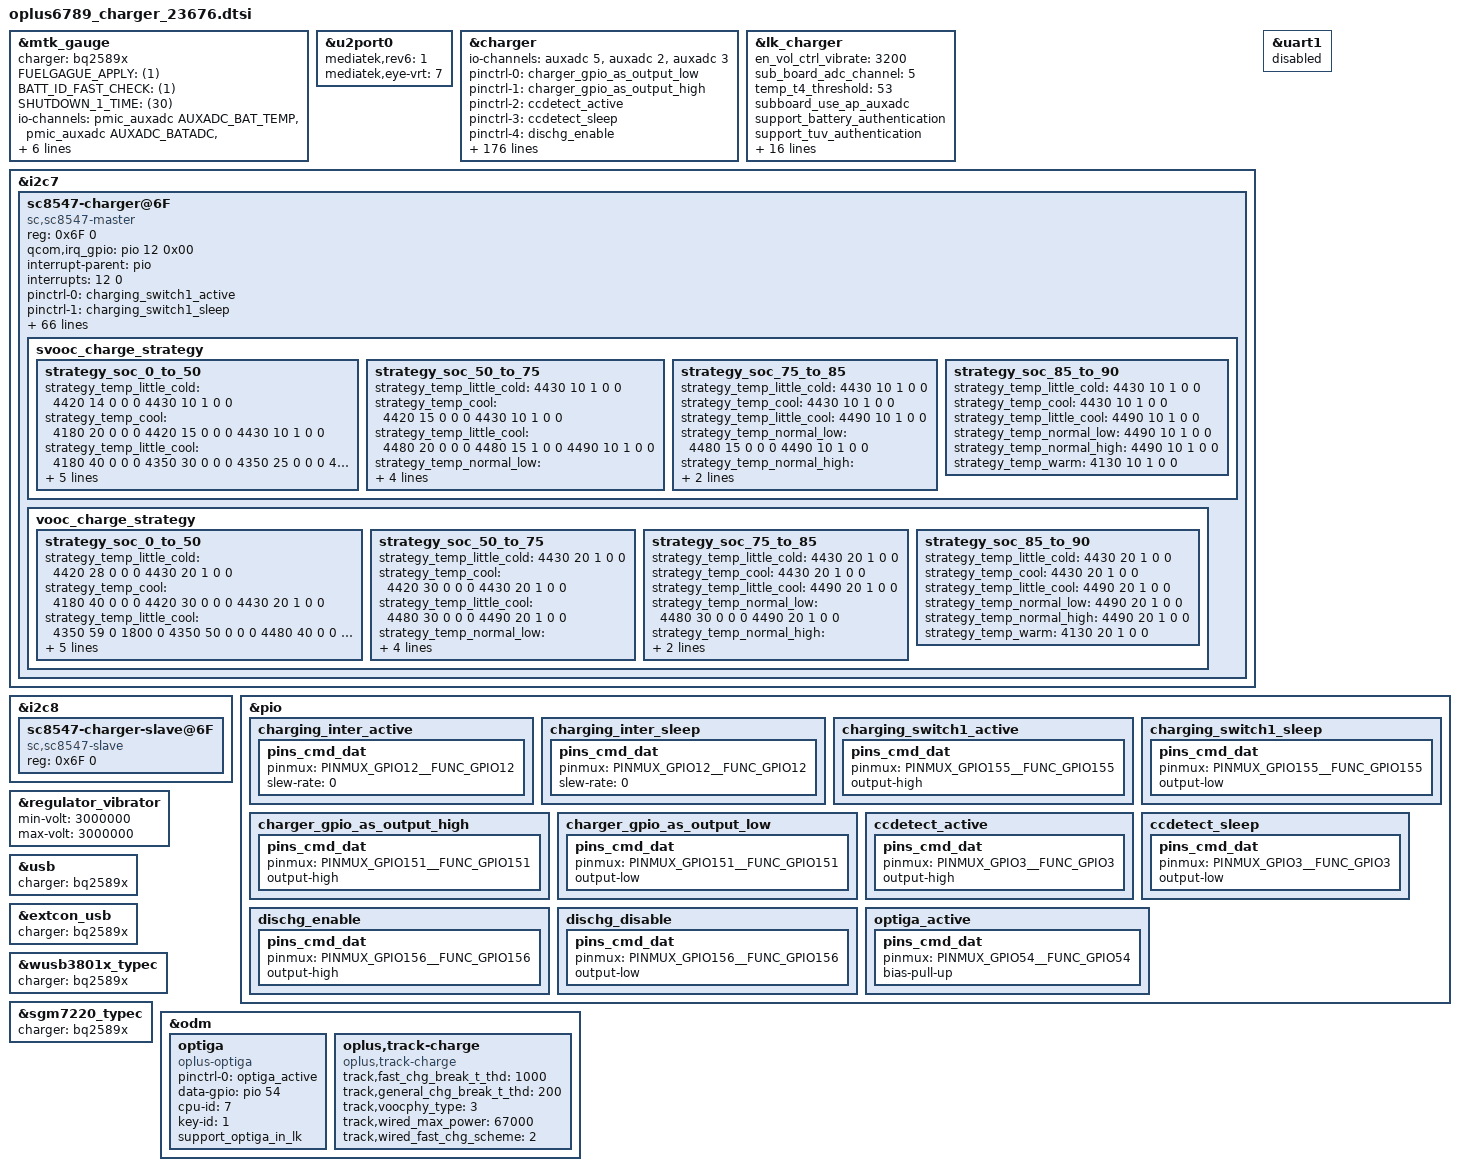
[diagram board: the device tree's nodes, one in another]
// SPDX-License-Identifier: GPL-2.0-only
/*
* Copyright (C) 2018-2020 Oplus. All rights reserved.
*/
/*
 *
 * CPU:MT6789 doki
 * IRQB
 * CHG_INT(cp irq)                --> GPIO12(CP1)/GPIO10(CP2)
 * CC_INTB(cc login irq)          --> GPIO3
 * EINT_CHG_M(main irq)           --> GPIO4
 *
 * GPIO
 * MAIN/CCLOGIN_SCL               --> GPIO48(SCL5)
 * MAIN/CCLOGIN_SDA               --> GPIO49(SDA5)
 * SW_CTRL(uart/vooc switch)      --> GPIO155(USB_SWITCH_2)
 * DISCHARGE_EN(防烧口)           -->
 * CHARGER_PUMP1_SCL               --> GPIO144(CP1_SCL7)
 * CHARGER_PUMP1_SDA               --> GPIO145(CP1_SDA7)
 * CHARGER_PUMP2_SCL               --> GPIO146(CP2_SCL8)
 * CHARGER_PUMP2_SDA               --> GPIO147(CP2_SDA8)
 * USB_ON(usb/uart&vooc switch)    --> GPIO151(USB_SWITCH_1)
 *
 * AUXADC:
 * 0				-->
 * 1				-->
 * 2				--> USB_TEM1_ADC
 * 3				--> USB_TEM2_ADC
 * 4				--> BAT_ID_ADC_OUT
 * 5				--> SUB_BAT_TEM
 * 6				-->
 * 7				-->
 * 8				-->
 */

#include <dt-bindings/iio/mt635x-auxadc.h>

&mtk_gauge {
	status = "okay";
	charger = <&bq2589x>;
	FUELGAGUE_APPLY = <(1)>;
	BATT_ID_FAST_CHECK = <(1)>;
	SHUTDOWN_1_TIME = <(30)>;
	io-channels = <&pmic_auxadc AUXADC_BAT_TEMP>,
				<&pmic_auxadc AUXADC_BATADC>,
				<&pmic_auxadc AUXADC_VBIF>,
				<&pmic_auxadc AUXADC_IMP>,
				<&pmic_auxadc AUXADC_IMIX_R>,
				<&auxadc 4>;
	io-channel-names = "pmic_battery_temp",
					"pmic_battery_voltage",
					"pmic_bif_voltage",
					"pmic_ptim_voltage",
					"pmic_ptim_r",
					 "auxadc4-batt_id_v";
	ntc_switch_gpio = <&pio 106 0x00>;
	// IS_SUBBOARD_TEMP_SUPPORT = <(1)>;
	EXTERNAL_AUTHENTICATE = <(1)>;
	Enable_Is_Force_Full = <(1)>;
	#include "mediatek/bat_setting/mt6789_23676_battery_prop_dim2_ext.dtsi"
	#include "mediatek/bat_setting/mt6789_23676_blp951_battery_table_ext.dtsi"
};

&u2port0 {
	mediatek,rev6 = <1>;
	mediatek,eye-vrt = <7>;
};

&charger {

	io-channels = <&auxadc 5>,<&auxadc 2>,<&auxadc 3>;
	io-channel-names = "auxadc5temp","usb_temp_v_l","usb_temp_v_r";

	pinctrl-names = "charger_gpio_as_output_low","charger_gpio_as_output_high",
					"ccdetect_active","ccdetect_sleep","dischg_enable","dischg_disable";
	pinctrl-0 = <&charger_gpio_as_output_low>;
	pinctrl-1 = <&charger_gpio_as_output_high>;
	pinctrl-2 = <&ccdetect_active>;
	pinctrl-3 = <&ccdetect_sleep>;
	pinctrl-4 = <&dischg_enable>;
	pinctrl-5 = <&dischg_disable>;

	gauge = <&mtk_gauge>;
	charger = <&bq2589x>;

	//for oplus chg framework:
	qcom,pd_input_current_charger_ma = <2000>;
	qcom,qc_input_current_charger_ma = <2000>;
	qcom,input_current_charger_ma = <2200>;
	qcom,input_current_usb_ma = <500>;
	qcom,input_current_cdp_ma = <1500>;
	qcom,input_current_camera_ma = <1200>;
	qcom,input_current_calling_ma = <1500>;

	qcom,led_warm_bat_decidegc = <350>;
	qcom,led_high_bat_decidegc = <370>;
	qcom,input_current_led_ma = <1200>;
	qcom,input_current_led_ma_high = <1200>;
	qcom,input_current_led_ma_warm = <1500>;
	qcom,input_current_led_ma_normal = <2000>;
	qcom,input_current_led_ma_forcmcc = <500>;
	qcom,input_current_led_ma_limit_high = <1200>;

	qcom,vooc_temp_bat_normal_decidegc = <350>;
	qcom,vooc_temp_bat_warm_decidegc = <370>;
	qcom,vooc_temp_bat_hot_decidegc = <440>;
	qcom,input_current_vooc_led_ma_high = <1200>;
	qcom,input_current_vooc_led_ma_warm = <1800>;
	qcom,input_current_vooc_led_ma_normal = <3600>;
	qcom,input_current_vooc_ma_normal = <3600>;
	qcom,input_current_vooc_ma_warm = <3200>;
	qcom,input_current_vooc_ma_high = <2200>;

	qcom,overtemp_bat_decidegc = <350>;
	qcom,iterm_disabled = <0>;
	//sw_full_count = <25>;
	qcom,iterm_ma = <255>;
	qcom,recharge-mv = <100>;

	qcom,batt_capacity_mah = <5000>; /*typical capacity*/
	//qcom,batt_capacity_mah = <4880>; /*rated capacity*/
	qcom,usb_high_than_bat_decidegc = <168>;

	qcom,removed_bat_decidegc = <390>;  /* < -39C */

	qcom,cold_bat_decidegc = <100>;  /* -10C ~ 0C */
	qcom,temp_cold_vfloat_mv = <4435>;
	qcom,temp_freeze_fastchg_current_ma_high = <900>;
	qcom,temp_freeze_fastchg_current_ma_low = <900>;
	qcom,temp_freeze_fastchg_current_ma = <900>;
	qcom,temp_cold_fastchg_current_ma = <900>;

	qcom,little_cold_bat_decidegc = <0>;    /* 0C ~ 5C */
	qcom,temp_little_cold_vfloat_mv = <4435>;
	qcom,temp_little_cold_fastchg_current_ma_high = <2200>;
	qcom,temp_little_cold_fastchg_current_ma_low = <2200>;
	qcom,temp_little_cold_fastchg_current_ma = <2200>;
	qcom,qc_temp_little_cold_fastchg_current_ma_high = <2594>;
	qcom,qc_temp_little_cold_fastchg_current_ma_low = <3300>;
	qcom,pd_temp_little_cold_fastchg_current_ma_high = <2594>;
	qcom,pd_temp_little_cold_fastchg_current_ma_low = <3300>;

	qcom,cool_bat_decidegc = <50>;  /* 5C ~ 12C */
	qcom,temp_cool_vfloat_mv = <4435>;
	qcom,temp_cool_fastchg_current_ma_high = <2200>;
	qcom,temp_cool_fastchg_current_ma_low = <2200>;
	qcom,qc_temp_cool_fastchg_current_ma_high = <3300>;
	qcom,qc_temp_cool_fastchg_current_ma_low = <3300>;
	qcom,pd_temp_cool_fastchg_current_ma_high = <3300>;
	qcom,pd_temp_cool_fastchg_current_ma_low = <3300>;

	qcom,little_cool_bat_decidegc = <120>;  /* 12C ~ 16C */
	qcom,temp_little_cool_vfloat_mv = <4435>;
	qcom,temp_little_cool_fastchg_current_ma = <2200>;
	qcom,pd_temp_little_cool_fastchg_current_ma = <3300>;
	qcom,qc_temp_little_cool_fastchg_current_ma = <3300>;

	qcom,normal_bat_decidegc = <160>;       /* 16C ~ 45C */
	qcom,temp_normal_vfloat_mv = <4435>;
	qcom,temp_normal_fastchg_current_ma = <2200>;
	qcom,pd_temp_normal_fastchg_current_ma = <3300>;
	qcom,qc_temp_normal_fastchg_current_ma = <3300>;

	qcom,warm_bat_decidegc = <450>;         /* 45C ~ 53C */ /*8pin Bat Vooc project need add 3 degree C*/
	qcom,temp_warm_vfloat_mv = <4130>;
	qcom,temp_warm_fastchg_current_ma = <1300>;
	qcom,pd_temp_warm_fastchg_current_ma = <1300>;
	qcom,qc_temp_warm_fastchg_current_ma = <1300>;
	qcom,temp_warm_fastchg_current_ma_led_on = <500>;

	qcom,hot_bat_decidegc = <530>;  /* > 53C */

	qcom,non_standard_vfloat_mv = <3980>;
	qcom,non_standard_fastchg_current_ma = <512>;

	qcom,short_c_bat_cv_mv = <4330>;
	qcom,short_c_bat_vfloat_mv = <3800>;
	qcom,short_c_bat_fastchg_current_ma = <512>;
	qcom,short_c_bat_vfloat_sw_limit = <3750>;

	qcom,cold_vfloat_sw_limit = <4385>;
	qcom,little_cold_vfloat_sw_limit = <4385>;
	qcom,cool_vfloat_sw_limit = <4385>;
	qcom,little_cool_vfloat_sw_limit = <4385>;
	qcom,normal_vfloat_sw_limit = <4385>;
	qcom,warm_vfloat_sw_limit = <4080>;
	qcom,non_standard_vfloat_sw_limit = <3930>;

	qcom,max_chg_time_sec = <72000>;
	qcom,charger_hv_thr = <10000>;
	qcom,charger_recv_thr = <9800>;
	qcom,charger_lv_thr = <3400>;
	qcom,vbatt_full_thr = <4400>;
	qcom,vbatt_hv_thr = <4600>;

	qcom,vfloat_step_mv = <16>;
	qcom,non_standard_vfloat_over_sw_limit = <3990>;
	qcom,cold_vfloat_over_sw_limit = <4445>;
	qcom,little_cold_vfloat_over_sw_limit = <4445>;
	qcom,cool_vfloat_over_sw_limit = <4445>;
	qcom,little_cool_vfloat_over_sw_limit = <4445>;
	qcom,normal_vfloat_over_sw_limit = <4440>;
	qcom,warm_vfloat_over_sw_limit = <4140>;

	qcom,vbatt_power_off = <3300>;
	qcom,vbatt_soc_1 = <3410>;
	qcom,vooc_project = <13>;
	qcom,vbatt_num = <1>;
	qcom,new_ui_warning_support;
	qcom,smart_charging_screenoff;
	qcom,smart_charge_version = <1>;

	qcom,normal_vterm_hw_inc = <18>;
	qcom,non_normal_vterm_hw_inc = <18>;
	qcom,usbtemp_batttemp_gap = <12>;

	qcom,ff1_normal_fastchg_ma = <1600>; /*16C~35c*/
	qcom,ff1_warm_fastchg_ma = <1700>;	/* 35C ~ 40c */
	qcom,ff1_exit_step_ma = <150>;
	qcom,ff1_warm_exit_step_ma = <150>;

	qcom,ffc2_normal_fastchg_ma = <1600>;/*16C~35c*/
	qcom,ffc2_warm_fastchg_ma = <1700>;	/* 35C ~ 40c */
	qcom,ffc2_temp_warm_decidegc = <350>;
	qcom,ffc2_temp_high_decidegc = <400>;
	qcom,ffc2_temp_low_decidegc = <160>;
	qcom,ffc2_exit_step_ma = <150>;
	qcom,ffc2_warm_exit_step_ma = <150>;

	qcom,ffc_normal_vfloat_sw_limit = <4485>;
	qcom,ffc_temp_normal_vfloat_mv = <4550>;
	qcom,ffc_normal_vfloat_over_sw_limit = <4550>;
	qcom,ffc_warm_vfloat_sw_limit = <4485>;

	qcom,ffc2_normal_vfloat_sw_limit = <4485>;
	qcom,ffc2_temp_normal_vfloat_mv = <4550>;
	qcom,ffc2_normal_vfloat_over_sw_limit = <4550>;
	qcom,ffc2_warm_vfloat_sw_limit = <4485>;


	qcom,default_iterm_ma = <255>;
	qcom,default_temp_normal_fastchg_current_ma = <2200>;
	qcom,default_normal_vfloat_sw_limit = <4385>;
	qcom,default_temp_normal_vfloat_mv = <4435>;
	qcom,default_normal_vfloat_over_sw_limit = <4445>;

	qcom,default_temp_little_cool_fastchg_current_ma = <2200>;
	qcom,default_little_cool_vfloat_sw_limit = <4385>;
	qcom,default_temp_little_cool_vfloat_mv = <4435>;
	qcom,default_little_cool_vfloat_over_sw_limit = <4445>;

	//for PD9V or QC9V
	qcom,vbatt_pdqc_to_5v_thr = <4500>;
	qcom,vbatt_pdqc_to_9v_thr = <4500>;

	//for control:
	qcom,support_subboard_ntc;
	qcom,support_abnormal_adapter;
	//qcom,suspend_after_full;
	qcom,check_batt_full_by_sw;
	qcom,chg_ctrl_by_lcd;
	qcom,chg_ctrl_by_camera;
	qcom,chg_ctrl_by_calling;
	qcom,sw_vfloat_over_protect_enable;
	qcom,usbtemp_dischg_by_platpmic;
	qcom,ffc_support;
	qcom,chargerid_vol_disable;
	qcom,support_ntc_01c_precision;
	qcom,voocphy_support = <(3)>;
	qcom,external_authenticate;
	qcom,chargerid_support;
	qcom,vooc_show_ui_soc_decimal;
	qcom,ui_soc_decimal_speedmin = <20>;//2A
	// qcom,ccdetect_by_wd0;
	qcom,hvdcp_disabled; //turn off hvdcp func for doki
	//GPIO config:
	qcom,chargerid_switch-gpio = <&pio 151 0x00>;
	qcom,dischg-gpio = <&pio 156 0x00>;
	//qcom,ccdetect-gpio = <&pio 3 0x00>;

	qcom,vooc-max-input-volt-support = <10000>;     //10V
	qcom,vooc-max-input-current-support = <6500>;   //6500mA
	//subboard NTC config:
	qcom,sub_board_pull_up_r = <200000>;
};

&lk_charger {
	en_vol_ctrl_vibrate = <3200>;
	sub_board_adc_channel = <5>;
	temp_t4_threshold = <53>;
	subboard_use_ap_auxadc;
	support_battery_authentication;
	support_tuv_authentication;
	charger_no_wiress;
	sub_board_temp_support;
	support_sdp_screenoff;
	support_sdp_backlight;
	max_charger_voltage = <15000000>;
	boot_battery_voltage = <3400000>;
	usb_charger_current = <500000>;
	ac_charger_current = <2050000>;
	ac_charger_input_current = <1500000>;
	non_std_ac_charger_current = <750000>;
	charging_host_charger_current = <1500000>;
	ta_ac_charger_current = <1500000>;
	pd_charger_current = <500000>;
	data-gpio = <54>;
	cpu-id = <7>;
	key-id = <1>;
};

&i2c7 {
	status = "okay";
	sc8547-charger@6F{
		status = "okay";
		compatible = "sc,sc8547-master";
		reg = <0x6F 0>;

		qcom,irq_gpio = <&pio 12 0x00>;
		interrupt-parent = <&pio>;
		interrupts = <12 0>;

		pinctrl-names = "switch1_act_switch2_act", "switch1_sleep_switch2_sleep",
					"charging_inter_active", "charging_inter_sleep";
		pinctrl-0 = <&charging_switch1_active>;
		pinctrl-1 = <&charging_switch1_sleep>;
		pinctrl-2 = <&charging_inter_active>;
		pinctrl-3 = <&charging_inter_sleep>;

		qcom,charging_switch1-gpio = <&pio 155 0x00>;

		ocp_reg = <10>;
		qcom,copycat_vooc_support;
		qcom,voocphy_dual_cp_support;
		qcom,slave_cp_enable_thr = <1900>;		//2000-100mA
		qcom,slave_cp_disable_thr_high = <1600>;	//1500+100mA
		qcom,voocphy_current_default = <61>;

		qcom,svooc_cool_down_current_limit = <122 20 20 24 30 34 40 44 50 54 60 64 70 74>;
		qcom,vooc_cool_down_current_limit = <61 20 20 24 30 34 40 44 50 54 60 64 70 74>;
		qcom,abnormal_adapter_current = <122 50 50 50 40 40 30 30 20 20>;

		qcom,vooc_multistep_initial_batt_temp = <1000>;

		qcom,vooc_strategy_normal_current = <122>;
		qcom,vooc_normal_to_little_cool_current = <100>;
		qcom,vooc_batt_over_high_temp = <500>;

		qcom,vooc-low-temp = <0>;
		qcom,vooc-high-temp = <500>;
		qcom,vooc-low-soc = <0>;
		qcom,vooc-high-soc = <90>;
		qcom,vooc-warm-allow-vol = <4000>;
		qcom,vooc-warm-allow-soc = <50>;

		qcom,vooc_little_cold_temp = <50>;
		qcom,vooc_cool_temp = <120>;
		qcom,vooc_little_cool_temp = <160>;
		qcom,vooc_normal_low_temp = <350>;
		qcom,vooc-normal-high-temp = <440>;

		qcom,vooc_strategy1_batt_high_temp0 = <395>;
		qcom,vooc_strategy1_batt_high_temp1 = <420>;
		qcom,vooc_strategy1_batt_high_temp2 = <440>;
		qcom,vooc_strategy1_batt_low_temp2 = <420>;
		qcom,vooc_strategy1_batt_low_temp1 = <395>;
		qcom,vooc_strategy1_batt_low_temp0 = <385>;

		qcom,vooc_strategy1_high_current0 = <80>;
		qcom,vooc_strategy1_high_current1 = <60>;
		qcom,vooc_strategy1_high_current2 = <40>;
		qcom,vooc_strategy1_low_current2 = <40>;
		qcom,vooc_strategy1_low_current1 = <60>;
		qcom,vooc_strategy1_low_current0 = <122>;

		qcom,voocphy_freq_mincore = <1800000>;
		qcom,voocphy_freq_midcore = <1800000>;
		qcom,voocphy_freq_maxcore = <1800000>;
		qcom,voocphy_current_change_timeout = <100>;

		qcom,voocphy_ibat_over_current = <13500>;
		qcom,voocphy_svooc_cp_max_ibus = <3500>;
		qcom,voocphy_vooc_cp_max_ibus = <3500>;
		qcom,voocphy_cp_max_ibus = <3500>;

		qcom,vooc_little_cold_full_voltage = <4430>;
		qcom,vooc_cool_full_voltage = <4430>;
		qcom,vooc_warm_full_voltage = <4130>;
		qcom,vooc_1time_full_voltage = <4500>;
		qcom,vooc_ntime_full_voltage = <4490>;
		qcom,low_curr_full_t1 = <120>;
		qcom,low_curr_full_t2 = <350>;
		qcom,low_curr_full_t3 = <430>;
		qcom,range1_low_curr_full = <1500 4490
						1400 4485
						1300 4470
						1200 4460
						1100 4450>;
		qcom,range2_low_curr_full = <1600 4490
						1400 4485
						1300 4470
						1200 4460
						1100 4450>;

		svooc_batt_sys_curve = <0 1 0 1 0 0 0	// 4000mA
					1 1 1 1 0 0 0	// 4604mV
					0 0 1 1 0 1 0	// 2600mA
					1 1 1 1 0 0 0	// 4604mV
					0 0 0 1 0 1 1	// 1100mA
					1 1 1 1 0 0 0>;	// 4604mV

		vooc_batt_sys_curve =  <0 1 0 1 0 0 0	// 4000mA
					1 1 1 1 0 0 0	// 4604mV
					0 0 1 1 0 1 0	// 2600mA
					1 1 1 1 0 0 0	// 4604mV
					0 0 0 1 0 1 1	// 1100mA
					1 1 1 1 0 0 0>;	// 4604mV

		svooc_charge_strategy {
			strategy_soc_0_to_50 {
				strategy_temp_little_cold =	<4420 14 0 0 0
								 4430 10 1 0 0>;
				strategy_temp_cool =	<4180 20 0 0 0
								 4420 15 0 0 0
								 4430 10 1 0 0>;
				strategy_temp_little_cool =	<4180 40 0 0 0
								 4350 30 0 0 0
								 4350 25 0 0 0
								 4480 20 0 0 0
								 4480 15 0 0 0
								 4490 10 1 0 0>;
				strategy_temp_normal_low =	<4200 61 0 240 0 //min*60*1000/500
								 4200 50 0 600 0 //min*60*1000/500
								 4350 40 0 0 0
								 4450 30 0 0 0
								 4450 25 0 0 0
								 4480 20 0 0 0
								 4480 15 0 0 0
								 4490 10 1 0 0>;
				strategy_temp_normal_high =	<4200 50 0 600 0 //min*60*1000/500
								 4350 40 0 1200 0 //min*60*1000/500
								 4450 30 0 0 0
								 4450 25 0 0 0
								 4480 20 0 0 0
								 4480 15 0 0 0
								 4490 10 1 0 0>;
				strategy_temp_warm = <4130 10 1 0 0>;
			};

			strategy_soc_50_to_75 {
				strategy_temp_little_cold =	<4430 10 1 0 0>;
				strategy_temp_cool =	<4420 15 0 0 0
								 4430 10 1 0 0>;
				strategy_temp_little_cool =	<4480 20 0 0 0
								 4480 15 1 0 0
								 4490 10 1 0 0>;
				strategy_temp_normal_low =	<4450 25 0 0 0
								 4480 20 0 1200 0
								 4480 15 0 0 0
								 4490 10 1 0 0>;
				strategy_temp_normal_high =	<4450 25 0 0 0
								 4480 20 0 1200 0
								 4480 15 0 0 0
								 4490 10 1 0 0>;
				strategy_temp_warm = <4130 10 1 0 0>;
			};

			strategy_soc_75_to_85 {
				strategy_temp_little_cold =	<4430 10 1 0 0>;
				strategy_temp_cool =	<4430 10 1 0 0>;
				strategy_temp_little_cool =	<4490 10 1 0 0>;
				strategy_temp_normal_low =	<4480 15 0 0 0
								 4490 10 1 0 0>;
				strategy_temp_normal_high =	<4480 15 0 0 0
								 4490 10 1 0 0>;
				strategy_temp_warm = <4130 10 1 0 0>;
			};

			strategy_soc_85_to_90 {
				strategy_temp_little_cold =	<4430 10 1 0 0>;
				strategy_temp_cool =	<4430 10 1 0 0>;
				strategy_temp_little_cool =	<4490 10 1 0 0>;
				strategy_temp_normal_low =	<4490 10 1 0 0>;
				strategy_temp_normal_high =	<4490 10 1 0 0>;
				strategy_temp_warm = <4130 10 1 0 0>;
			};
		};

		vooc_charge_strategy {
			strategy_soc_0_to_50 {
				strategy_temp_little_cold =	<4420 28 0 0 0
								 4430 20 1 0 0>; /*0-5C*/
				strategy_temp_cool =	<4180 40 0 0 0
								 4420 30 0 0 0
								 4430 20 1 0 0>;			/*5-12C*/
				strategy_temp_little_cool =	<4350 59 0 1800 0 //min*60*1000/500
								 4350 50 0 0 0
								 4480 40 0 0 0
								 4480 30 0 0 0
								 4490 20 1 0 0>;			/*12-16C*/
				strategy_temp_normal_low =	<4450 59 0 1800 0 //min*60*1000/500
								 4450 50 0 0 0
								 4480 40 0 0 0
								 4480 30 0 0 0
								 4490 20 1 0 0>;			/*16-25C*/
				strategy_temp_normal_high =	<4450 59 0 1800 0 //min*60*1000/500
								 4450 50 0 0 0
								 4480 40 0 0 0
								 4480 30 0 0 0
								 4490 20 1 0 0>;			/*25C-44C*/
				strategy_temp_warm = <4130 20 1 0 0>;
			};

			strategy_soc_50_to_75 {
				strategy_temp_little_cold =	<4430 20 1 0 0>;
				strategy_temp_cool =	<4420 30 0 0 0
								 4430 20 1 0 0>;
				strategy_temp_little_cool =	<4480 30 0 0 0
								 4490 20 1 0 0>;
				strategy_temp_normal_low =	<4450 50 0 0 0
								 4480 40 0 0 0
								 4480 30 0 0 0
								 4490 20 1 0 0>;
				strategy_temp_normal_high =	<4450 50 0 0 0
								 4480 40 0 0 0
								 4480 30 0 0 0
								 4490 20 1 0 0>;
				strategy_temp_warm = <4130 20 1 0 0>;
			};

			strategy_soc_75_to_85 {
				strategy_temp_little_cold =	<4430 20 1 0 0>;
				strategy_temp_cool =	<4430 20 1 0 0>;
				strategy_temp_little_cool =	<4490 20 1 0 0>;
				strategy_temp_normal_low =	<4480 30 0 0 0
								 4490 20 1 0 0>;
				strategy_temp_normal_high =	<4480 30 0 0 0
								 4490 20 1 0 0>;
				strategy_temp_warm = <4130 20 1 0 0>;
			};

			strategy_soc_85_to_90 {
				strategy_temp_little_cold =	<4430 20 1 0 0>;
				strategy_temp_cool =	<4430 20 1 0 0>;
				strategy_temp_little_cool =	<4490 20 1 0 0>;
				strategy_temp_normal_low =	<4490 20 1 0 0>;
				strategy_temp_normal_high =	<4490 20 1 0 0>;
				strategy_temp_warm = <4130 20 1 0 0>;
			};
		};

	};
};

&i2c8 {
	status = "okay";
	sc8547-charger-slave@6F{
		status = "okay";
		compatible = "sc,sc8547-slave";
		reg = <0x6F 0>;
	};
};

&uart1 {
	status = "disabled";
};

&pio {
	charging_inter_active: charging_inter_active {
		pins_cmd_dat {
			pinmux = <PINMUX_GPIO12__FUNC_GPIO12>;
			slew-rate = <0>;
		};
	};

	charging_inter_sleep: charging_inter_sleep {
		pins_cmd_dat {
			pinmux = <PINMUX_GPIO12__FUNC_GPIO12>;
			slew-rate = <0>;
		};
	};

	charging_switch1_active: charging_switch1_active {
		pins_cmd_dat {
			pinmux = <PINMUX_GPIO155__FUNC_GPIO155>;
			output-high;
		};
	};

	charging_switch1_sleep: charging_switch1_sleep {
		pins_cmd_dat {
			pinmux = <PINMUX_GPIO155__FUNC_GPIO155>;
			output-low;
		};
	};

	charger_gpio_as_output_high: charger_gpio_as_output_high {
		pins_cmd_dat {
			pinmux = <PINMUX_GPIO151__FUNC_GPIO151>;
			output-high;
		};
	};
	charger_gpio_as_output_low: charger_gpio_as_output_low {
		pins_cmd_dat {
			pinmux = <PINMUX_GPIO151__FUNC_GPIO151>;
			output-low;
		};
	};
	ccdetect_active: ccdetect_active {
		pins_cmd_dat {
			pinmux = <PINMUX_GPIO3__FUNC_GPIO3>;
			output-high;
		};
	};
	ccdetect_sleep: ccdetect_sleep {
		pins_cmd_dat {
			pinmux = <PINMUX_GPIO3__FUNC_GPIO3>;
			output-low;
		};
	};
	dischg_enable: dischg_enable {
		pins_cmd_dat {
			pinmux = <PINMUX_GPIO156__FUNC_GPIO156>;
			output-high;
		};
	};
	dischg_disable: dischg_disable {
		pins_cmd_dat {
			pinmux = <PINMUX_GPIO156__FUNC_GPIO156>;
			output-low;
		};
	};
};

&regulator_vibrator{
	min-volt = <3000000>;
	max-volt = <3000000>;
};

&usb {
	charger = <&bq2589x>;
	status = "okay";
};

&extcon_usb {
	charger = <&bq2589x>;
	status = "okay";
};

&charger {
	charger = <&bq2589x>;
	status = "okay";
};

&wusb3801x_typec {
	charger = <&bq2589x>;
	status = "okay";
};

&sgm7220_typec {
	charger = <&bq2589x>;
	status = "okay";
};

&odm {
	optiga {
		compatible = "oplus-optiga";
		status = "ok";
		pinctrl-names = "optiga_active";
		pinctrl-0 = <&optiga_active>;
		data-gpio = <&pio 54 0x00>;
		cpu-id = <7>;
		key-id = <1>;
		support_optiga_in_lk;
	};

	oplus,track-charge {
		compatible = "oplus,track-charge";
		track,fast_chg_break_t_thd = <1000>;
		track,general_chg_break_t_thd = <200>;
		track,voocphy_type = <3>;
		track,wired_max_power = <67000>;
		track,wired_fast_chg_scheme = <2>;
	};
};


&pio {
	optiga_active: optiga_active {
		pins_cmd_dat {
			pinmux = <PINMUX_GPIO54__FUNC_GPIO54>;
			//slew-rate = <1>;
			bias-pull-up;
		};
	};
};
